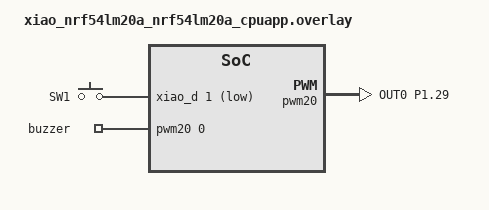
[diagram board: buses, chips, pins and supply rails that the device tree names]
/ {
	buttons {
		xiao_button1: button_1 {
			gpios = <&xiao_d 1 (GPIO_PULL_UP | GPIO_ACTIVE_LOW)>;
			label = "SW1";
			zephyr,code = <INPUT_KEY_0>;
		};
	};

	/* Use pwm-leds binding to expose buzzer through DT alias */
	pwm_leds {
		compatible = "pwm-leds";
		buzzer: buzzer {
			pwms = <&pwm20 0 PWM_MSEC(20) PWM_POLARITY_NORMAL>;
			status = "okay";
		};
	};

	aliases {
		sw1 = &xiao_button1;
		buzzer = &buzzer;
	};
};

&pwm20 {
	status = "okay";
	pinctrl-0 = <&pwm20_buzzer_default>;
	pinctrl-1 = <&pwm20_buzzer_sleep>;
	pinctrl-names = "default", "sleep";
};

&pinctrl {
	pwm20_buzzer_default: pwm20_buzzer_default {
		group1 {
			/* XIAO D3 = P1.29 on nRF54LM20A */
			psels = <NRF_PSEL(PWM_OUT0, 1, 29)>;
		};
	};

	pwm20_buzzer_sleep: pwm20_buzzer_sleep {
		group1 {
			psels = <NRF_PSEL(PWM_OUT0, 1, 29)>;
			low-power-enable;
		};
	};
};
